# Polarfire SoC register map
Vendor: Microchip; File version: 1.0
CPU: Microchip PolarFire SoC 1.0, little endian
Registers are 32-bit, read-write, reset 0x0 unless marked. A register's access mark holds for its fields unless they carry their own. Offsets are from the block's base; [hi:lo] are bit positions.

## QSPIXIP — QSPIXIP Controller
Base 0x21000000
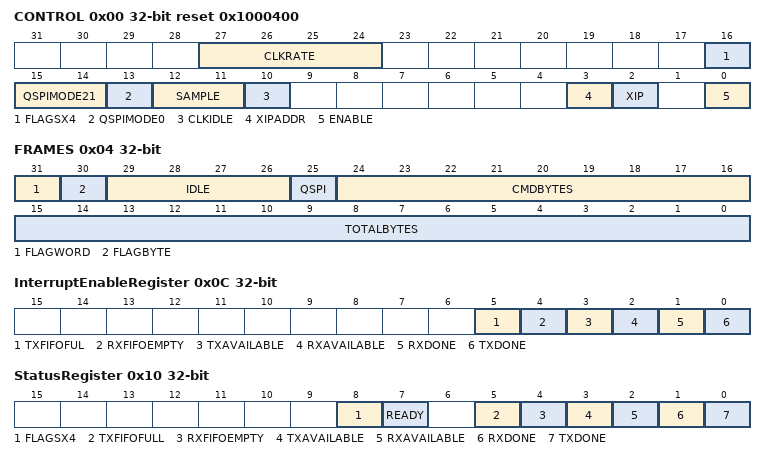
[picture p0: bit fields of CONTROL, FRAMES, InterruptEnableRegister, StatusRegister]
0x00 CONTROL reset 0x1000400
  [27:24] CLKRATE — Sets the SPI clock rate (master mode) 0: Not Supported N: SPICLK = HCLK/(2*N) No. can vary from 2-15 allowing rates from HCLK/4(Max) to HCLK/30(Min)
  [16] FLAGSX4 — This register bits should be set before x4 are used to read and write data. It modifies the FIFO status signals to indicate that four bytes may be read or written.
  [15:14] QSPIMODE21 — Sets whether multiple bit SPI operates in normal extended or full modes: 00: Normal (single DQ0 TX and single DQ1 RX lines) 01: Extended RO (command and address bytes on DQ0 only) 10: Extended RW (command byte on DQ0 only) 11: Full. (command and address bytes are on all DQ lines)
  [13] QSPIMODE0 — Sets whether multiple bit SPI uses 2 or 4 bits of data 0: 2-bits (BSPI) 1: 4-bits (QSPI)
  [12:11] SAMPLE — Sets when the core samples SDI in master mode 00: At the rising edge off SPI CLOCK allowing half a SPI clock period round trip delay Other values are not supported.
  [10] CLKIDLE — Sets the clock IDLE to low (0) or high (1).Allows the core to support SPI memory operation in mode 0 or mode 3. When CLKRATE=0 this bit has no effect; the clock IDLE state will always be 1
  [3] XIPADDR — Sets the number of bytes used for the address in XIP mode (1'b0 = 3 bytes 1'b1 = 4 Bytes)
  [2] XIP — 0: Normal operation 1: XIP mode
  [0] ENABLE — 0: Core will not respond to external signals until this bit enabled 1: Core is active
0x04 FRAMES — This register is only functional in master mode. It is used to start a master transfer.
  [31] FLAGWORD — If set then the FIFO flags are set to word mode.This sets the FLAGX4 bit in the control register.This bit always reads as zero
  [30] FLAGBYTE — If set then the FIFO flags are set to byte mode This clears the FLAGX4 bit in the control register.This bit always reads as zero
  [29:26] IDLE — This sets the number of IDLE cycles to be inserted between the TX and RX SPI phases 0 to 15
  [25] QSPI — 0: Normal Operation 1: QSPI Mode (2 or 4-bits data as set in control register)
  [24:16] CMDBYTES — Sets the number of bytes that create the SPI command 0- 511. When zero the SPI simply transmits a byte when written to the transmit FIFO and writes the received byte to the receive FIFO. When non zero the logic will transmit data from the receive FIFO and discard receive data until CMDBYTES have been transmitted It will the automatically transmit the remaining number of bytes (TOTLABYTES) writing the received data into the receive FIFO
  [15:0] TOTALBYTES — Number of bytes to be sent/received, 1 to 65535. This register once set will not change an internal counter counts until it reaches the limit set by this register When this register is written the internal counter is also reset. When that counter reaches TOTALBYTES interrupts are generated and idle cycles inserted on the SPI bus (SSEL deactivated). The core will transmit data whenever the transmit FIFO is loaded the counter is used to count bytes terminate bursts and generate interrupts
0x0C InterruptEnableRegister — This is interrupt enable register for external register.
  [5] TXFIFOFUL
  [4] RXFIFOEMPTY
  [3] TXAVAILABLE
  [2] RXAVAILABLE
  [1] RXDONE
  [0] TXDONE — Enables the external interrupt for the corresponding interrupt.
0x10 StatusRegister ro — Indicates the status of the SPI core.
  [8] FLAGSX4 — Read of CONTROL registers FLAGSX4. Allows Firmware to check the value at the same time as the status.
  [7] READY — Indicates that the SPI master is IDLE and a new transmission may be started.
  [5] TXFIFOFULL — Indicates that the TX Fifo is full or contains less than 4-empty locations when FLAGSX4 set.
  [4] RXFIFOEMPTY — Indicates that the RX Fifo is empty or contains less than 4-bytes when FLAGSX4 set.
  [3] TXAVAILABLE — Indicates that there is room for at least one or four (FLAGSX4 set) bytes in the transmit FIFO.
  [2] RXAVAILABLE — Indicates that there is at least one or four (FLAGSX4 set) received bytes available in the receive FIFO.
  [1] RXDONE — Indicates that all the frames have been received and the RX FIFO is empty Is cleared by writing 1 or when the FRAMES register is written.
  [0] TXDONE — Indicates that all the frames have been transmitted.Is cleared by writing 1 or when the FRAMES register is written.
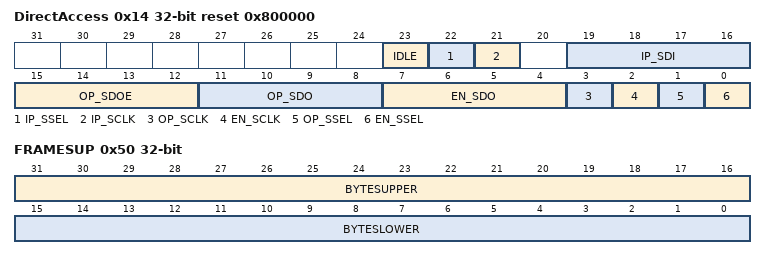
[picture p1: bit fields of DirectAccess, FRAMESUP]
0x14 DirectAccess reset 0x800000 — This register allows direct access to the QSPI interface pins to support access to non-standard SPI devices via direct CPU control.
  [23] IDLE ro — Master SPI FSM is stalled/idle
  [22] IP_SSEL ro — Current SSEL value
  [21] IP_SCLK ro — Current SCLK value
  [19:16] IP_SDI ro — Input data on SDI
  [15:12] OP_SDOE — Output enables for SDATA
  [11:8] OP_SDO — Output value for SDATA
  [7:4] EN_SDO — Enable this register to drive SDATA data and output enable
  [3] OP_SCLK — Value driven on SCLK
  [2] EN_SCLK — Enable this register to drive SCLK
  [1] OP_SSEL — Value driven on SSEL
  [0] EN_SSEL — Enable this register to drive SSEL
0x18 UpperAddress — This register set the upper 8-bits of the address [31:24] when four byte addressing is being used in XIP mode.
  [7:0] ADDRUP — Sets the upper address bits [31:24] in XIP mode.
0x40 ReceiveData ro
  [7:0] RXDATA — Received data - single byte
0x44 TransmitData
  [7:0] TXDATA — Data to send - single byte
0x48 X4ReceiveData ro — Allows the processor to read 4-bytes from the SPI FIFO in a single transaction. Reads will return 4-bytes as APB reads are always words (PSTRB only used on writes)
  [31:0] RXDATA4 — Returns 4-bytes off receive data
0x4C X4TransmitData ro — Allows the processor to write 4-bytes from the SPI FIFO in a single transaction. Writes to this register must use word operations i.e. write 4-bytes at a time.
  [31:0] TXDATA4 rw — Writes 4-bytes of data to send;
0x50 FRAMESUP
  [31:16] BYTESUPPER
  [15:0] BYTESLOWER — W: NO operation R: Return the lower 16 - bits of the byte count from the FRAMES register
